# S6E2DF register map
File version: 1.1
CPU: CM4 r0p1, little endian, MPU, FPU, 4 interrupt priority bits
Registers are 32-bit, read-write, reset 0x0 unless marked. A register's access mark holds for its fields unless they carry their own. Offsets are from the block's base; [hi:lo] are bit positions; {n}, {i} and the like mark numbered series; 'fields as' and 'values as' point back to an identical list.

## MFT_PPG — PPG Configuration
Base 0x40024000
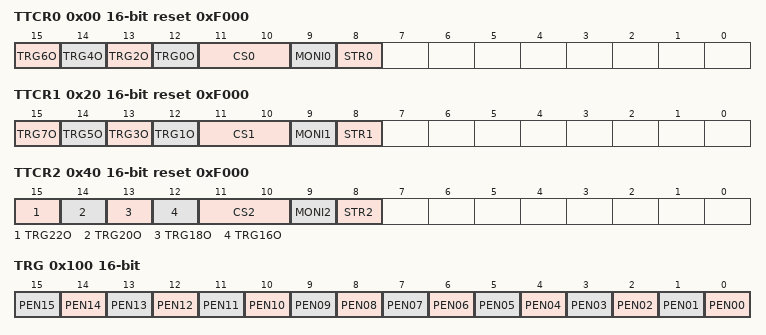
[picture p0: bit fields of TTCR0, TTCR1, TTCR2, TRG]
0x00 TTCR0 16-bit reset 0xF000 — PPG Start Trigger Control Register 0
  [15] TRG6O — PPG6 trigger stop bit
  [14] TRG4O — PPG4 trigger stop bit
  [13] TRG2O — PPG2 trigger stop bit
  [12] TRG0O — PPG0 trigger stop bit
  [11:10] CS0 — 8-bit UP counter clock select bits for comparison
  [9] MONI0 ro — 8-bit UP counter operation state monitor bit for comparison
  [8] STR0 — 8-bit UP counter operation enable bit for comparison
0x08 COMP0 16-bit (reset mask 0xFF00) — PPG Compare Register 0
0x0C COMP2 8-bit — PPG Compare Register 2
0x10 COMP4 16-bit (reset mask 0xFF00) — PPG Compare Register 4
0x14 COMP6 8-bit — PPG Compare Register 6
0x20 TTCR1 16-bit reset 0xF000 — PPG Start Trigger Control Register 1
  [15] TRG7O — PPG7 trigger stop bit
  [14] TRG5O — PPG5 trigger stop bit
  [13] TRG3O — PPG3 trigger stop bit
  [12] TRG1O — PPG1 trigger stop bit
  [11:10] CS1 — 8-bit UP counter clock select bits for comparison
  [9] MONI1 ro — 8-bit UP counter operation state monitor bit for comparison
  [8] STR1 — 8-bit UP counter operation enable bit for comparison
0x28 COMP1 16-bit (reset mask 0xFF00) — PPG Compare Register 1
0x2C COMP3 8-bit — PPG Compare Register 3
0x30 COMP5 16-bit (reset mask 0xFF00) — PPG Compare Register 5
0x34 COMP7 8-bit — PPG Compare Register 7
0x40 TTCR2 16-bit reset 0xF000 — PPG Start Trigger Control Register 2
  [15] TRG22O — PPG22 trigger stop bit
  [14] TRG20O — PPG20 trigger stop bit
  [13] TRG18O — PPG18 trigger stop bit
  [12] TRG16O — PPG16 trigger stop bit
  [11:10] CS2 — 8-bit UP counter clock select bits for comparison
  [9] MONI2 ro — 8-bit UP counter operation state monitor bit for comparison
  [8] STR2 — 8-bit UP counter operation enable bit for comparison
0x48 COMP8 16-bit (reset mask 0xFF00) — PPG Compare Register 8
0x4C COMP10 8-bit — PPG Compare Register 10
0x50 COMP12 16-bit (reset mask 0xFF00) — PPG Compare Register 12
0x54 COMP14 8-bit — PPG Compare Register 14
0x100 TRG 16-bit — PPG Start Register 0
  [n] PEN{n:02} (n=0..15) — PPG{n} Start Trigger bit
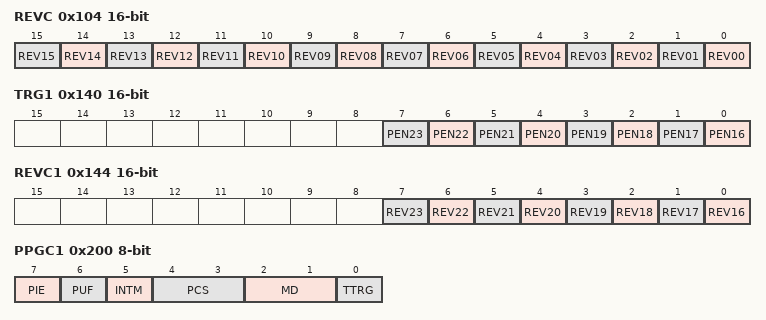
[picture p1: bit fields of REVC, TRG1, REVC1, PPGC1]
0x104 REVC 16-bit — Output Reverse Register 0
  [n] REV{n:02} (n=0..15) — PPG{n} Output Reverse Enable bit
0x140 TRG1 16-bit — PPG Start Register 1
  [n-16] PEN{n} (n=16..23) — PPG{n} Start Trigger bit
0x144 REVC1 16-bit — Output Reverse Register 1
  [n-16] REV{n} (n=16..23) — PPG{n} Output Reverse Enable bit
0x200 PPGC1 8-bit — PPG Operation Mode Control Register 1
  [7] PIE — PPG Interrupt Enable bit
  [6] PUF — PPG Counter Underflow bit
  [5] INTM — Interrupt Mode Select bit
  [4:3] PCS — PPG DOWN Counter Operation Clock Select bits
  [2:1] MD — PPG Operation Mode Set bits
  [0] TTRG — PPG start trigger select bit
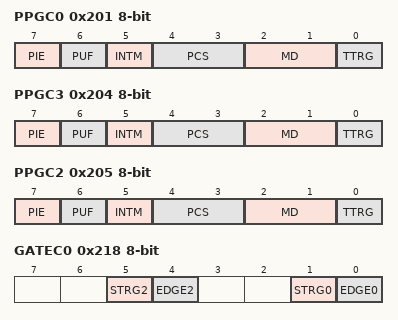
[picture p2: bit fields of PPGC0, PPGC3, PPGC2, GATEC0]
0x201 PPGC0 8-bit — PPG Operation Mode Control Register 0
  fields as PPGC1
0x204 PPGC3 8-bit — PPG Operation Mode Control Register 3
  fields as PPGC1
0x205 PPGC2 8-bit — PPG Operation Mode Control Register 2
  fields as PPGC1
{0x208+4i} PRLL{i} 8-bit reset not defined (i=0..3) — PPG{i} Reload Registers Low
  [7:0] PRLL — Reload Registers Low
{0x209+4i} PRLH{i} 8-bit reset not defined (i=0..3) — PPG{i} Reload Registers High
  [7:0] PRLH — Reload Registers High
0x218 GATEC0 8-bit — PPG Gate Function Control Registers 0
  [5] STRG2 — Select a trigger for PPG2
  [4] EDGE2 — Select Start Effective Level for PPG2
  [1] STRG0 — Select a trigger for PPG0
  [0] EDGE0 — Select Start Effective Level for PPG0
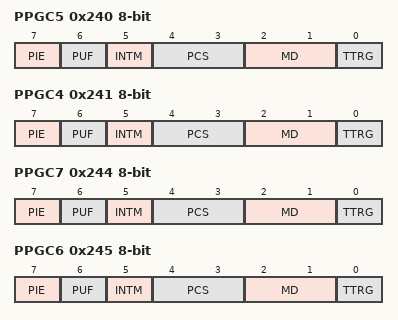
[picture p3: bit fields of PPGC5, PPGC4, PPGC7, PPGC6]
0x240 PPGC5 8-bit — PPG Operation Mode Control Register 5
  fields as PPGC1
0x241 PPGC4 8-bit — PPG Operation Mode Control Register 4
  fields as PPGC1
0x244 PPGC7 8-bit — PPG Operation Mode Control Register 7
  fields as PPGC1
0x245 PPGC6 8-bit — PPG Operation Mode Control Register 6
  fields as PPGC1
{0x238+4i} PRLL{i} 8-bit reset not defined (i=4..7) — PPG{i} Reload Registers Low
  [7:0] PRLL — Reload Registers Low
{0x239+4i} PRLH{i} 8-bit reset not defined (i=4..7) — PPG{i} Reload Registers High
  [7:0] PRLH — Reload Registers High
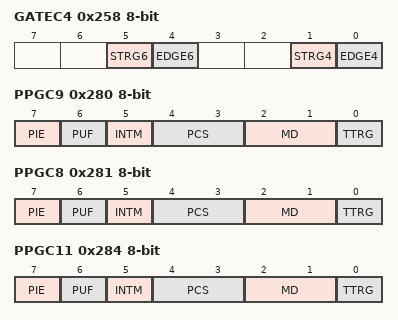
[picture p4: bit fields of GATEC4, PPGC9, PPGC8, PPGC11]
0x258 GATEC4 8-bit — PPG Gate Function Control Registers 4
  [5] STRG6 — Select a trigger for PPG6
  [4] EDGE6 — Select Start Effective Level for PPG6
  [1] STRG4 — Select a trigger for PPG4
  [0] EDGE4 — Select Start Effective Level for PPG4
0x280 PPGC9 8-bit — PPG Operation Mode Control Register 9
  fields as PPGC1
0x281 PPGC8 8-bit — PPG Operation Mode Control Register 8
  fields as PPGC1
0x284 PPGC11 8-bit — PPG Operation Mode Control Register 11
  fields as PPGC1
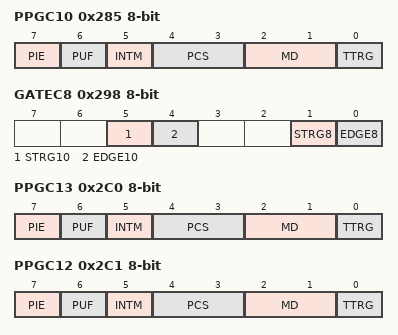
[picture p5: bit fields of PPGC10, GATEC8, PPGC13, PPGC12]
0x285 PPGC10 8-bit — PPG Operation Mode Control Register 10
  fields as PPGC1
{0x268+4i} PRLL{i} 8-bit reset not defined (i=8..11) — PPG{i} Reload Registers Low
  [7:0] PRLL — Reload Registers Low
{0x269+4i} PRLH{i} 8-bit reset not defined (i=8..11) — PPG{i} Reload Registers High
  [7:0] PRLH — Reload Registers High
0x298 GATEC8 8-bit — PPG Gate Function Control Registers 8
  [5] STRG10 — Select a trigger for PPG10
  [4] EDGE10 — Select Start Effective Level for PPG10
  [1] STRG8 — Select a trigger for PPG8
  [0] EDGE8 — Select Start Effective Level for PPG8
0x2C0 PPGC13 8-bit — PPG Operation Mode Control Register 13
  fields as PPGC1
0x2C1 PPGC12 8-bit — PPG Operation Mode Control Register 12
  fields as PPGC1
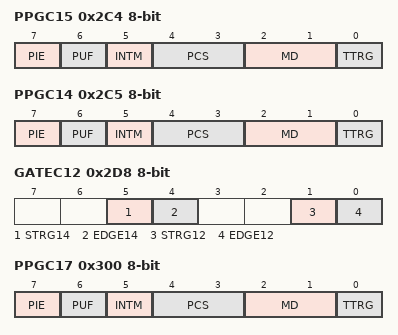
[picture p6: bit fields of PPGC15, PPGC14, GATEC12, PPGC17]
0x2C4 PPGC15 8-bit — PPG Operation Mode Control Register 15
  fields as PPGC1
0x2C5 PPGC14 8-bit — PPG Operation Mode Control Register 14
  fields as PPGC1
{0x298+4i} PRLL{i} 8-bit reset not defined (i=12..15) — PPG{i} Reload Registers Low
  [7:0] PRLL — Reload Registers Low
{0x299+4i} PRLH{i} 8-bit reset not defined (i=12..15) — PPG{i} Reload Registers High
  [7:0] PRLH — Reload Registers High
0x2D8 GATEC12 8-bit — PPG Gate Function Control Registers 12
  [5] STRG14 — Select a trigger for PPG14
  [4] EDGE14 — Select Start Effective Level for PPG14
  [1] STRG12 — Select a trigger for PPG12
  [0] EDGE12 — Select Start Effective Level for PPG12
0x300 PPGC17 8-bit — PPG Operation Mode Control Register 17
  fields as PPGC1
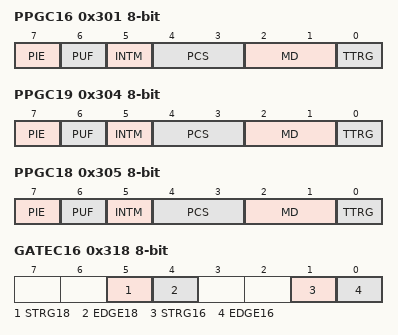
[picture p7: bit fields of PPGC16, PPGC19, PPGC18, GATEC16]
0x301 PPGC16 8-bit — PPG Operation Mode Control Register 16
  fields as PPGC1
0x304 PPGC19 8-bit — PPG Operation Mode Control Register 19
  fields as PPGC1
0x305 PPGC18 8-bit — PPG Operation Mode Control Register 18
  fields as PPGC1
{0x2C8+4i} PRLL{i} 8-bit reset not defined (i=16..19) — PPG{i} Reload Registers Low
  [7:0] PRLL — Reload Registers Low
{0x2C9+4i} PRLH{i} 8-bit reset not defined (i=16..19) — PPG{i} Reload Registers High
  [7:0] PRLH — Reload Registers High
0x318 GATEC16 8-bit — PPG Gate Function Control Registers 16
  [5] STRG18 — Select a trigger for PPG18
  [4] EDGE18 — Select Start Effective Level for PPG18
  [1] STRG16 — Select a trigger for PPG16
  [0] EDGE16 — Select Start Effective Level for PPG16
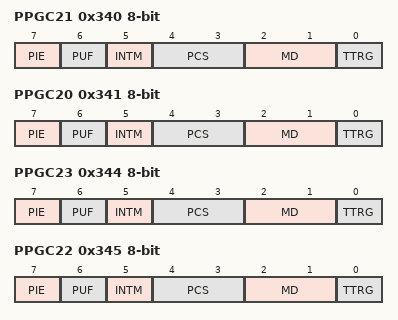
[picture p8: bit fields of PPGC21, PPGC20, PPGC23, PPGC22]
0x340 PPGC21 8-bit — PPG Operation Mode Control Register 21
  fields as PPGC1
0x341 PPGC20 8-bit — PPG Operation Mode Control Register 20
  fields as PPGC1
0x344 PPGC23 8-bit — PPG Operation Mode Control Register 23
  fields as PPGC1
0x345 PPGC22 8-bit — PPG Operation Mode Control Register 22
  fields as PPGC1
{0x2F8+4i} PRLL{i} 8-bit reset not defined (i=20..23) — PPG{i} Reload Registers Low
  [7:0] PRLL — Reload Registers Low
{0x2F9+4i} PRLH{i} 8-bit reset not defined (i=20..23) — PPG{i} Reload Registers High
  [7:0] PRLH — Reload Registers High
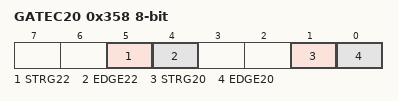
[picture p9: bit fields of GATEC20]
0x358 GATEC20 8-bit — PPG Gate Function Control Registers 20
  [5] STRG22 — Select a trigger for PPG22
  [4] EDGE22 — Select Start Effective Level for PPG22
  [1] STRG20 — Select a trigger for PPG20
  [0] EDGE20 — Select Start Effective Level for PPG20

## Notices in the file
Copyright (C) 2015 Spansion LLC. All Rights Reserved.
This software is owned and published by:
Spansion LLC, 915 DeGuigne Dr. Sunnyvale, CA  94088-3453 ("Spansion").
BY DOWNLOADING, INSTALLING OR USING THIS SOFTWARE, YOU AGREE TO BE BOUND
BY ALL THE TERMS AND CONDITIONS OF THIS AGREEMENT.
This software contains source code for use with Spansion
components. This software is licensed by Spansion to be adapted only
for use in systems utilizing Spansion components. Spansion shall not be
responsible for misuse or illegal use of this software for devices not
supported herein.  Spansion is providing this software "AS IS" and will
not be responsible for issues arising from incorrect user implementation
of the software.
SPANSION MAKES NO WARRANTY, EXPRESS OR IMPLIED, ARISING BY LAW OR OTHERWISE,
REGARDING THE SOFTWARE (INCLUDING ANY ACOOMPANYING WRITTEN MATERIALS),
ITS PERFORMANCE OR SUITABILITY FOR YOUR INTENDED USE, INCLUDING,
WITHOUT LIMITATION, THE IMPLIED WARRANTY OF MERCHANTABILITY, THE IMPLIED
WARRANTY OF FITNESS FOR A PARTICULAR PURPOSE OR USE, AND THE IMPLIED
WARRANTY OF NONINFRINGEMENT.
SPANSION SHALL HAVE NO LIABILITY (WHETHER IN CONTRACT, WARRANTY, TORT,
NEGLIGENCE OR OTHERWISE) FOR ANY DAMAGES WHATSOEVER (INCLUDING, WITHOUT
LIMITATION, DAMAGES FOR LOSS OF BUSINESS PROFITS, BUSINESS INTERRUPTION,
LOSS OF BUSINESS INFORMATION, OR OTHER PECUNIARY LOSS) ARISING FROM USE OR
INABILITY TO USE THE SOFTWARE, INCLUDING, WITHOUT LIMITATION, ANY DIRECT,
INDIRECT, INCIDENTAL, SPECIAL OR CONSEQUENTIAL DAMAGES OR LOSS OF DATA,
SAVINGS OR PROFITS,
EVEN IF SPANSION HAS BEEN ADVISED OF THE POSSIBILITY OF SUCH DAMAGES.
YOU ASSUME ALL RESPONSIBILITIES FOR SELECTION OF THE SOFTWARE TO ACHIEVE YOUR
INTENDED RESULTS, AND FOR THE INSTALLATION OF, USE OF, AND RESULTS OBTAINED
FROM, THE SOFTWARE.
This software may be replicated in part or whole for the licensed use,
with the restriction that this Disclaimer and Copyright notice must be
included with each copy of this software, whether used in part or whole,
at all times.
